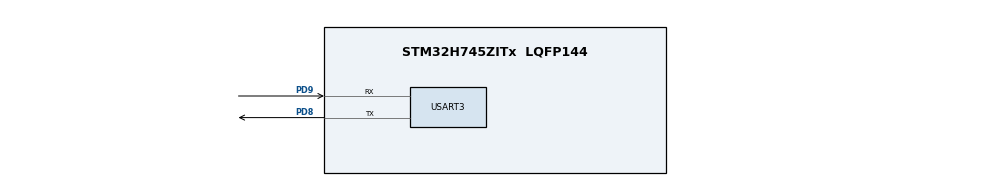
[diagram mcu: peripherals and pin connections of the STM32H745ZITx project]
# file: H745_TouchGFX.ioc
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CORTEX_M7.CPU_DCache=Enabled
CORTEX_M7.CPU_ICache=Enabled
CortexM4.IPs=FATFS_M4\:I,FREERTOS_M4\:I,IWDG2\:I,RCC,WWDG2\:I,DMA,BDMA,MDMA,NVIC2\:I,DEBUG,USB_DEVICE_M4\:I,USB_HOST_M4\:I,PDM2PCM_M4\:I,PWR,RESMGR_UTILITY,SYS_M4\:I,CORTEX_M4\:I,OPENAMP_M4\:I,VREFBUF,GPIO
CortexM7.IPs=FATFS_M7\:I,FREERTOS_M7\:I,IWDG1\:I,RCC\:I,WWDG1\:I,DMA\:I,BDMA\:I,MDMA\:I,NVIC1\:I,SYS\:I,USART3\:I,CORTEX_M7\:I,DEBUG\:I,USB_DEVICE_M7\:I,USB_HOST_M7\:I,PDM2PCM_M7\:I,PWR\:I,RESMGR_UTILITY\:I,OPENAMP_M7\:I,VREFBUF\:I,GPIO\:I,CRC\:I
Mcu.Family=STM32H7
Mcu.Name=STM32H745ZITx
Mcu.Package=LQFP144
NVIC1.PriorityGroup=NVIC_PRIORITYGROUP_4
NVIC2.PriorityGroup=NVIC_PRIORITYGROUP_4
PC14-OSC32_IN\ (OSC32_IN).Mode=LSE-External-Clock-Source
PC14-OSC32_IN\ (OSC32_IN).PinAttribute=Free
PC14-OSC32_IN\ (OSC32_IN).Signal=RCC_OSC32_IN
PD8.Mode=Asynchronous
PD8.PinAttribute=CortexM7
PD8.Signal=USART3_TX
PD9.Mode=Asynchronous
PD9.PinAttribute=CortexM7
PD9.Signal=USART3_RX
PH0-OSC_IN\ (PH0).Mode=HSE-External-Clock-Source
PH0-OSC_IN\ (PH0).PinAttribute=Free
PH0-OSC_IN\ (PH0).Signal=RCC_OSC_IN
ProjectManager.HeapSize=M4-0x200,M7-0x400
ProjectManager.StackSize=M4-0x400,M7-0x800
ProjectManager.TargetToolchain=STM32CubeIDE
RCC.ADCFreq_Value=129000000
RCC.APB1Freq_Value=100000000
RCC.APB2Freq_Value=100000000
RCC.APB3Freq_Value=100000000
RCC.APB4Freq_Value=100000000
RCC.CortexFreq_Value=400000000
RCC.D1PPRE=RCC_APB3_DIV2
RCC.D2PPRE1=RCC_APB1_DIV2
RCC.D2PPRE2=RCC_APB2_DIV2
RCC.D3PPRE=RCC_APB4_DIV2
RCC.DIVM1=4
RCC.DIVM3=1
RCC.DIVN1=50
RCC.DIVN3=18
RCC.DIVQ1=5
RCC.DIVQ3=3
RCC.HCLKFreq_Value=200000000
RCC.HPRE=RCC_HCLK_DIV2
RCC.HSE_VALUE=8000000
RCC.PLL2FRACN=0
RCC.PLL3FRACN=6144
RCC.PLLFRACN=0
RCC.PWR_Regulator_Voltage_Scale=PWR_REGULATOR_VOLTAGE_SCALE0
RCC.SYSCLKFreq_VALUE=400000000
RCC.SYSCLKSource=RCC_SYSCLKSOURCE_PLLCLK
RCC.SupplySource=PWR_EXTERNAL_SOURCE_SUPPLY
RCC.USBCLockSelection=RCC_USBCLKSOURCE_PLL3
RCC.USBFreq_Value=400000000
USART3.VirtualMode-Asynchronous=VM_ASYNC
VP_SYS_M4_VS_Systick.Mode=SysTick
board=NUCLEO-H745ZI-Q

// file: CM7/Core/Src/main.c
/* USER CODE BEGIN Header */
/**
  ******************************************************************************
  * @file           : main.c
  * @brief          : Main program body
  ******************************************************************************
  * @attention
  *
  * Copyright (c) 2023 STMicroelectronics.
  * All rights reserved.
  *
  * This software is licensed under terms that can be found in the LICENSE file
  * in the root directory of this software component.
  * If no LICENSE file comes with this software, it is provided AS-IS.
  *
  ******************************************************************************
  */
/* USER CODE END Header */
#include "main.h"
#include "usart.h"
#include "gpio.h"

/* USER CODE BEGIN PD */

#ifndef HSEM_ID_0
#define HSEM_ID_0 (0U) /* HW semaphore 0*/
#endif

/* USER CODE END PD */

void SystemClock_Config(void);

int main(void)
{
/* USER CODE BEGIN Boot_Mode_Sequence_0 */
  int32_t timeout;
/* USER CODE END Boot_Mode_Sequence_0 */

  /* Enable I-Cache---------------------------------------------------------*/
  SCB_EnableICache();

  /* Enable D-Cache---------------------------------------------------------*/
  SCB_EnableDCache();

/* USER CODE BEGIN Boot_Mode_Sequence_1 */
  /* Wait until CPU2 boots and enters in stop mode or timeout*/
  timeout = 0xFFFF;

  while((__HAL_RCC_GET_FLAG(RCC_FLAG_D2CKRDY) != RESET) && (timeout-- > 0));
  if ( timeout < 0 )
  {
	  Error_Handler();
  }
  /*
  while(__HAL_RCC_GET_FLAG(RCC_FLAG_D2CKRDY) != RESET) {
	  asm("nop");
  }
  */
/* USER CODE END Boot_Mode_Sequence_1 */
  /* MCU Configuration--------------------------------------------------------*/

  /* Reset of all peripherals, Initializes the Flash interface and the Systick. */
  HAL_Init();

  /* Configure the system clock */
  SystemClock_Config();
/* USER CODE BEGIN Boot_Mode_Sequence_2 */
/* When system initialization is finished, Cortex-M7 will release Cortex-M4 by means of
HSEM notification */
/*HW semaphore Clock enable*/
__HAL_RCC_HSEM_CLK_ENABLE();
/*Take HSEM */
HAL_HSEM_FastTake(HSEM_ID_0);
/*Release HSEM in order to notify the CPU2(CM4)*/
HAL_HSEM_Release(HSEM_ID_0,0);
/* wait until CPU2 wakes up from stop mode */
timeout = 0xFFFF;
while((__HAL_RCC_GET_FLAG(RCC_FLAG_D2CKRDY) == RESET) && (timeout-- > 0));
if ( timeout < 0 )
{
Error_Handler();
}
/* USER CODE END Boot_Mode_Sequence_2 */

  /* Initialize all configured peripherals */
  MX_GPIO_Init();
  MX_USART3_UART_Init();

  /* Infinite loop */
  /* USER CODE BEGIN WHILE */
  while (1)
  {
	  HAL_UART_Transmit(&huart3, "Hello from CM7\r\n", 17, 0xFFFF);
	  HAL_Delay(1000);
    /* USER CODE END WHILE */

  }
}

void SystemClock_Config(void)
{
  RCC_OscInitTypeDef RCC_OscInitStruct = {0};
  RCC_ClkInitTypeDef RCC_ClkInitStruct = {0};

  /** Supply configuration update enable
  */
  HAL_PWREx_ConfigSupply(PWR_EXTERNAL_SOURCE_SUPPLY);

  /** Configure the main internal regulator output voltage
  */
  __HAL_PWR_VOLTAGESCALING_CONFIG(PWR_REGULATOR_VOLTAGE_SCALE0);

  while(!__HAL_PWR_GET_FLAG(PWR_FLAG_VOSRDY)) {}

  /** Initializes the RCC Oscillators according to the specified parameters
  * in the RCC_OscInitTypeDef structure.
  */
  RCC_OscInitStruct.OscillatorType = RCC_OSCILLATORTYPE_HSI;
  RCC_OscInitStruct.HSIState = RCC_HSI_DIV1;
  RCC_OscInitStruct.HSICalibrationValue = RCC_HSICALIBRATION_DEFAULT;
  RCC_OscInitStruct.PLL.PLLState = RCC_PLL_ON;
  RCC_OscInitStruct.PLL.PLLSource = RCC_PLLSOURCE_HSI;
  RCC_OscInitStruct.PLL.PLLM = 4;
  RCC_OscInitStruct.PLL.PLLN = 50;
  RCC_OscInitStruct.PLL.PLLP = 2;
  RCC_OscInitStruct.PLL.PLLQ = 5;
  RCC_OscInitStruct.PLL.PLLR = 2;
  RCC_OscInitStruct.PLL.PLLRGE = RCC_PLL1VCIRANGE_3;
  RCC_OscInitStruct.PLL.PLLVCOSEL = RCC_PLL1VCOWIDE;
  RCC_OscInitStruct.PLL.PLLFRACN = 0;
  if (HAL_RCC_OscConfig(&RCC_OscInitStruct) != HAL_OK)
  {
    Error_Handler();
  }

  /** Initializes the CPU, AHB and APB buses clocks
  */
  RCC_ClkInitStruct.ClockType = RCC_CLOCKTYPE_HCLK|RCC_CLOCKTYPE_SYSCLK
                              |RCC_CLOCKTYPE_PCLK1|RCC_CLOCKTYPE_PCLK2
                              |RCC_CLOCKTYPE_D3PCLK1|RCC_CLOCKTYPE_D1PCLK1;
  RCC_ClkInitStruct.SYSCLKSource = RCC_SYSCLKSOURCE_PLLCLK;
  RCC_ClkInitStruct.SYSCLKDivider = RCC_SYSCLK_DIV1;
  RCC_ClkInitStruct.AHBCLKDivider = RCC_HCLK_DIV2;
  RCC_ClkInitStruct.APB3CLKDivider = RCC_APB3_DIV2;
  RCC_ClkInitStruct.APB1CLKDivider = RCC_APB1_DIV2;
  RCC_ClkInitStruct.APB2CLKDivider = RCC_APB2_DIV2;
  RCC_ClkInitStruct.APB4CLKDivider = RCC_APB4_DIV2;

  if (HAL_RCC_ClockConfig(&RCC_ClkInitStruct, FLASH_LATENCY_2) != HAL_OK)
  {
    Error_Handler();
  }
}

void Error_Handler(void)
{
  __disable_irq();
  while (1)
  {
  }
}
